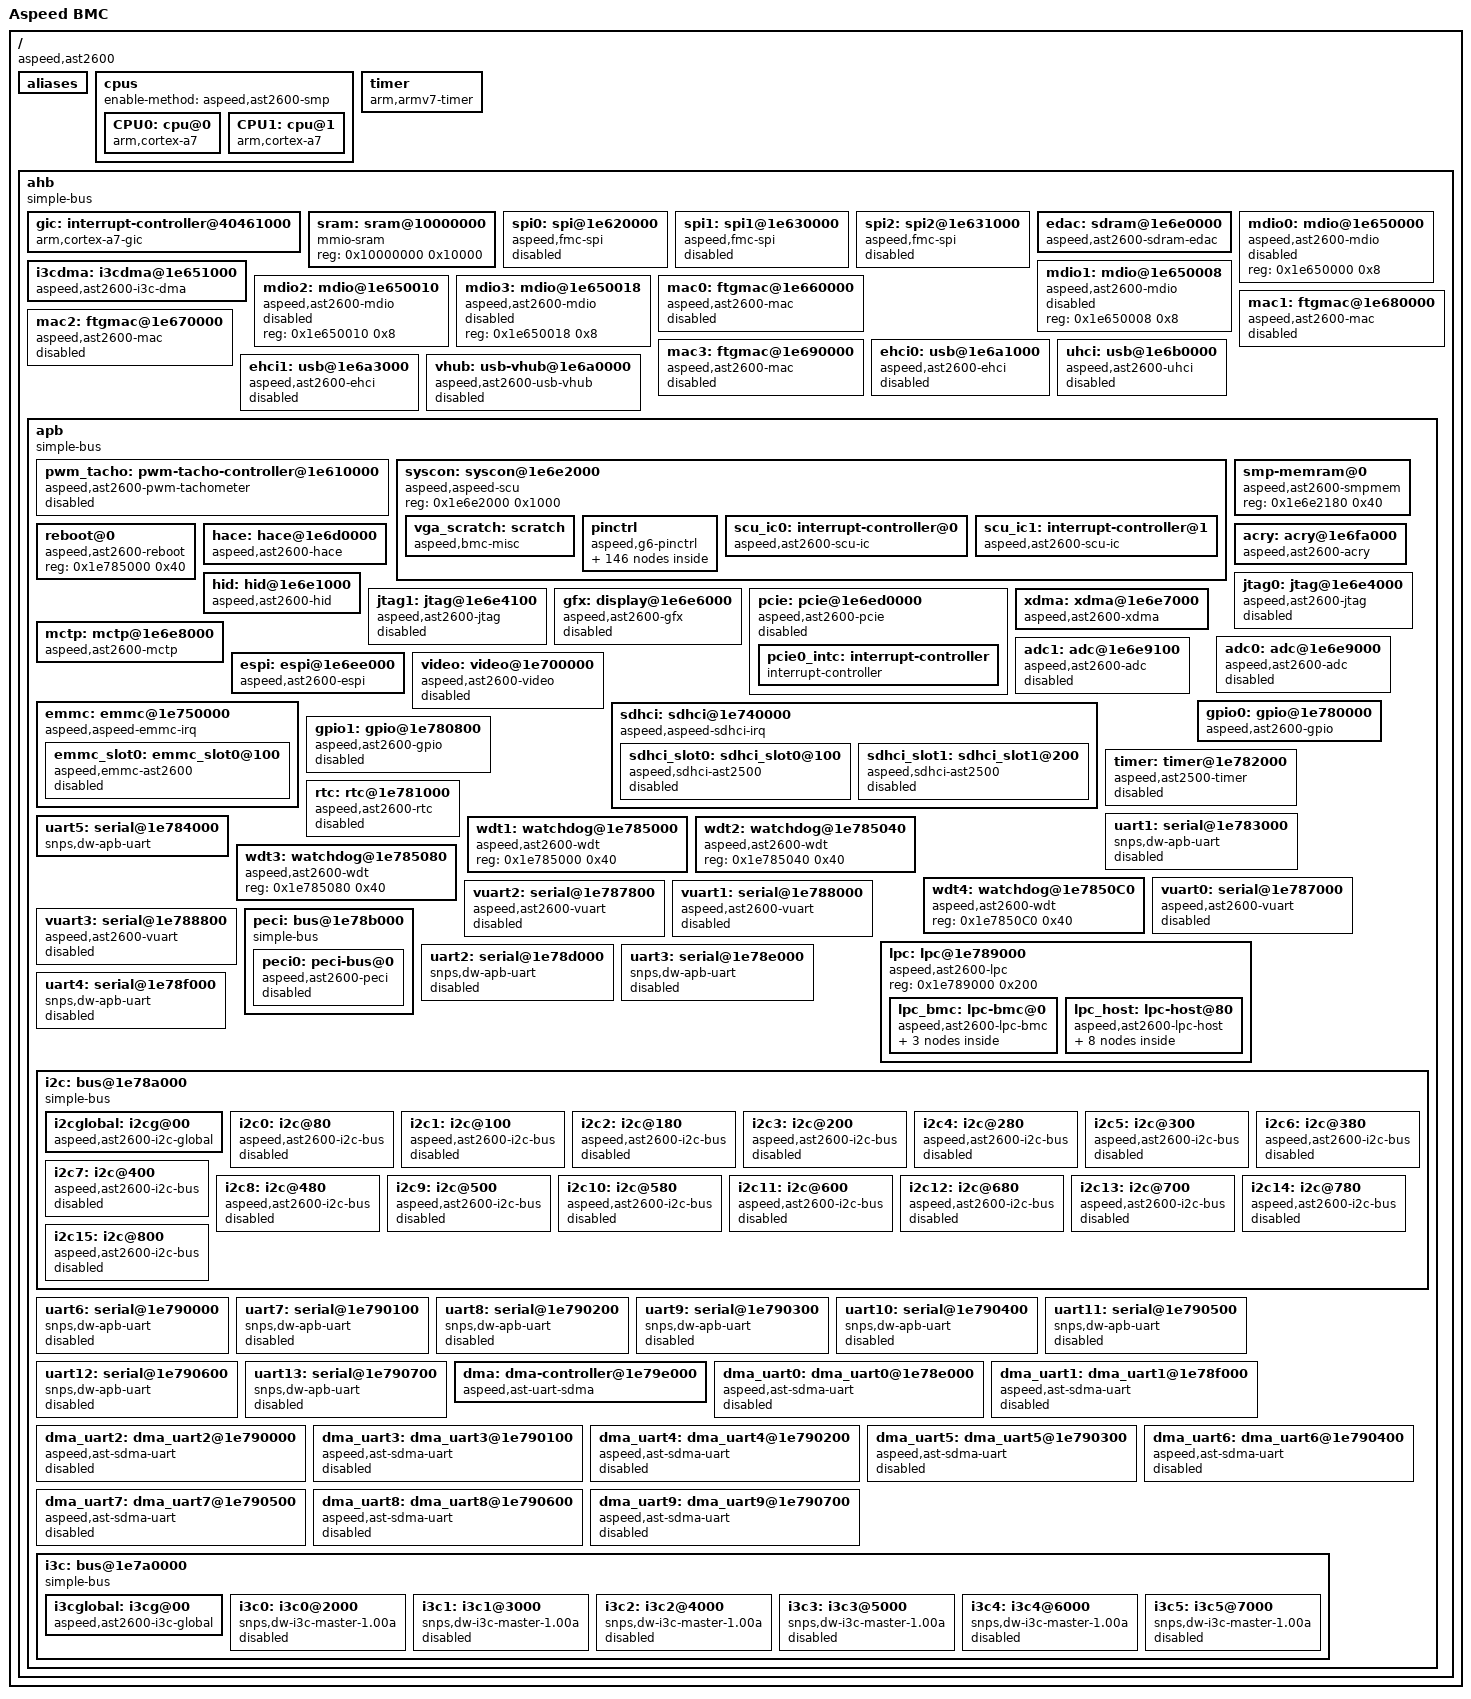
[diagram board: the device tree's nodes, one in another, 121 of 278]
// SPDX-License-Identifier: GPL-2.0+
#include <dt-bindings/interrupt-controller/arm-gic.h>
#include <dt-bindings/clock/aspeed-g6-clock.h>
#include <dt-bindings/gpio/aspeed-gpio.h>
#include <dt-bindings/interrupt-controller/aspeed-scu-irq.h>

/ {
	model = "Aspeed BMC";
	compatible = "aspeed,ast2600";
	#address-cells = <1>;
	#size-cells = <1>;
	interrupt-parent = <&gic>;

	aliases {
		i3c0 = &i3c0;
		i3c1 = &i3c1;
		i3c2 = &i3c2;
		i3c3 = &i3c3;
		i3c4 = &i3c4;
		i3c5 = &i3c5;
		i2c0 = &i2c0;
		i2c1 = &i2c1;
		i2c2 = &i2c2;
		i2c3 = &i2c3;
		i2c4 = &i2c4;
		i2c5 = &i2c5;
		i2c6 = &i2c6;
		i2c7 = &i2c7;
		i2c8 = &i2c8;
		i2c9 = &i2c9;
		i2c10 = &i2c10;
		i2c11 = &i2c11;
		i2c12 = &i2c12;
		i2c13 = &i2c13;
		i2c14 = &i2c14;
		i2c15 = &i2c15;
		serial0 = &uart1;
		serial1 = &uart2;
		serial2 = &uart3;
		serial3 = &uart4;
		serial4 = &uart5;
		serial5 = &uart6;
		serial6 = &uart7;
		serial7 = &uart8;
		serial8 = &uart9;
		serial9 = &uart10;
		serial10 = &uart11;
		serial11 = &uart12;
		serial12 = &uart13;
		serial13 = &vuart0;
		serial14 = &vuart1;
		serial15 = &vuart2;
		serial16 = &vuart3;
		peci0 = &peci0;
	};

	cpus {
		#address-cells = <1>;
		#size-cells = <0>;
		enable-method = "aspeed,ast2600-smp";

		CPU0: cpu@0 {
			compatible = "arm,cortex-a7";
			device_type = "cpu";
			reg = <0xf00>;
			clocks = <&syscon ASPEED_CLK_HPLL>;
		};

		CPU1: cpu@1 {
			compatible = "arm,cortex-a7";
			device_type = "cpu";
			reg = <0xf01>;
			clocks = <&syscon ASPEED_CLK_HPLL>;
		};

	};

	timer {
		compatible = "arm,armv7-timer";
		interrupt-parent = <&gic>;
		interrupts = <GIC_PPI 13 (GIC_CPU_MASK_SIMPLE(2) | IRQ_TYPE_LEVEL_LOW)>,
				<GIC_PPI 14 (GIC_CPU_MASK_SIMPLE(2) | IRQ_TYPE_LEVEL_LOW)>,
				<GIC_PPI 11 (GIC_CPU_MASK_SIMPLE(2) | IRQ_TYPE_LEVEL_LOW)>,
				<GIC_PPI 10 (GIC_CPU_MASK_SIMPLE(2) | IRQ_TYPE_LEVEL_LOW)>;
		clocks = <&syscon ASPEED_CLK_HPLL>;
		arm,cpu-registers-not-fw-configured;
	};

	ahb {
		compatible = "simple-bus";
		#address-cells = <1>;
		#size-cells = <1>;
		device_type = "soc";
		ranges;

		gic: interrupt-controller@40461000 {
				compatible = "arm,cortex-a7-gic";
				interrupts = <GIC_PPI 9 (GIC_CPU_MASK_SIMPLE(2) | IRQ_TYPE_LEVEL_HIGH)>;
				#interrupt-cells = <3>;
				interrupt-controller;
				interrupt-parent = <&gic>;
				reg = <0x40461000 0x1000>,
					<0x40462000 0x1000>,
					<0x40464000 0x2000>,
					<0x40466000 0x2000>;
		};

		sram: sram@10000000 {
			compatible = "mmio-sram";
			reg = <0x10000000 0x10000>;      // 64K
		};

		spi0: spi@1e620000 {
			/* reg : cs0 : cs1 : cs2  */
			reg = <0x1e620000 0x100 
					0x20000000 0x20 
					0x28000000 0x20>;
			#address-cells = <1>;
			#size-cells = <0>;
			compatible = "aspeed,fmc-spi";
			clocks = <&syscon ASPEED_CLK_AHB>;
			status = "disable";
			number_of_chip_select = /bits/ 16 <2>;
			interrupts = <GIC_SPI 39 IRQ_TYPE_LEVEL_HIGH>;
		};

		spi1: spi1@1e630000 {
			/* reg : cs0 : cs1 */
			reg = <0x1e630000 0x100 
					0x30000000 0x20 
					0x32000000 0x20>;
			#address-cells = <1>;
			#size-cells = <0>;
			compatible = "aspeed,fmc-spi";
			clocks = <&syscon ASPEED_CLK_AHB>;
			status = "disable";
			number_of_chip_select = /bits/ 8 <2>;
		};

		spi2: spi2@1e631000 {
			/* reg : cs0 : cs1 */
			reg = <0x1e631000 0x100 
					0x38000000 0x20 
					0x3A000000 0x20>;
			#address-cells = <1>;
			#size-cells = <0>;
			compatible = "aspeed,fmc-spi";
			clocks = <&syscon ASPEED_CLK_AHB>;
			status = "disable";
			number_of_chip_select = /bits/ 8 <2>;
		};

		edac: sdram@1e6e0000 {
			compatible = "aspeed,ast2600-sdram-edac";
			reg = <0x1e6e0000 0x174>;
			interrupts = <GIC_SPI 0 IRQ_TYPE_LEVEL_HIGH>;
		};

		i3cdma: i3cdma@1e651000 {
			compatible = "aspeed,ast2600-i3c-dma";
			reg = <0x1e651000 0x1000>;
			resets = <&syscon ASPEED_RESET_I3C>;
		};

		mdio0: mdio@1e650000 {
			compatible = "aspeed,ast2600-mdio";
			reg = <0x1e650000 0x8>;
			#address-cells = <1>;
			#size-cells = <0>;
			status = "disabled";
		};

		mdio1: mdio@1e650008 {
			compatible = "aspeed,ast2600-mdio";
			reg = <0x1e650008 0x8>;
			#address-cells = <1>;
			#size-cells = <0>;
			status = "disabled";
		};

		mdio2: mdio@1e650010 {
			compatible = "aspeed,ast2600-mdio";
			reg = <0x1e650010 0x8>;
			#address-cells = <1>;
			#size-cells = <0>;
			status = "disabled";
		};

		mdio3: mdio@1e650018 {
			compatible = "aspeed,ast2600-mdio";
			reg = <0x1e650018 0x8>;
			#address-cells = <1>;
			#size-cells = <0>;
			status = "disabled";
		};

		mac0: ftgmac@1e660000 {
			compatible = "aspeed,ast2600-mac", "faraday,ftgmac100";
			reg = <0x1e660000 0x180>;
			#address-cells = <1>;
			#size-cells = <0>;
			interrupts = <GIC_SPI 2 IRQ_TYPE_LEVEL_HIGH>;
			clocks = <&syscon ASPEED_CLK_GATE_MAC1CLK>;

			status = "disabled";
		};

		mac1: ftgmac@1e680000 {
			compatible = "aspeed,ast2600-mac", "faraday,ftgmac100";
			reg = <0x1e680000 0x180>;
			#address-cells = <1>;
			#size-cells = <0>;
			interrupts = <GIC_SPI 3 IRQ_TYPE_LEVEL_HIGH>;
			clocks = <&syscon ASPEED_CLK_GATE_MAC2CLK>;

			status = "disabled";
		};

		mac2: ftgmac@1e670000 {
			compatible = "aspeed,ast2600-mac", "faraday,ftgmac100";
			reg = <0x1e670000 0x180>;
			#address-cells = <1>;
			#size-cells = <0>;
			interrupts = <GIC_SPI 32 IRQ_TYPE_LEVEL_HIGH>;
			clocks = <&syscon ASPEED_CLK_GATE_MAC3CLK>;

			status = "disabled";
		};

		mac3: ftgmac@1e690000 {
			compatible = "aspeed,ast2600-mac", "faraday,ftgmac100";
			reg = <0x1e690000 0x180>;
			#address-cells = <1>;
			#size-cells = <0>;
			interrupts = <GIC_SPI 33 IRQ_TYPE_LEVEL_HIGH>;
			clocks = <&syscon ASPEED_CLK_GATE_MAC4CLK>;

			status = "disabled";
		};

		ehci0: usb@1e6a1000 {
			compatible = "aspeed,ast2600-ehci", "generic-ehci";
			reg = <0x1e6a1000 0x100>;
			interrupts = <GIC_SPI 5 IRQ_TYPE_LEVEL_HIGH>;
			clocks = <&syscon ASPEED_CLK_GATE_USBPORT1CLK>;
			pinctrl-names = "default";
			pinctrl-0 = <&pinctrl_usb2ah_default>;
			status = "disabled";
		};

		ehci1: usb@1e6a3000 {
			compatible = "aspeed,ast2600-ehci", "generic-ehci";
			reg = <0x1e6a3000 0x100>;
			interrupts = <GIC_SPI 9 IRQ_TYPE_LEVEL_HIGH>;
			clocks = <&syscon ASPEED_CLK_GATE_USBPORT2CLK>;
			pinctrl-names = "default";
			pinctrl-0 = <&pinctrl_usb2bh_default>;
			status = "disabled";
		};

		uhci: usb@1e6b0000 {
			compatible = "aspeed,ast2600-uhci", "generic-uhci";
			reg = <0x1e6b0000 0x100>;
			interrupts = <GIC_SPI 10 IRQ_TYPE_LEVEL_HIGH>;
			#ports = <2>;
			clocks = <&syscon ASPEED_CLK_GATE_USBUHCICLK>;
			status = "disabled";
		};

		vhub: usb-vhub@1e6a0000 {
			compatible = "aspeed,ast2600-usb-vhub";
			reg = <0x1e6a0000 0x300>;
			interrupts = <GIC_SPI 5 IRQ_TYPE_LEVEL_HIGH>;
			clocks = <&syscon ASPEED_CLK_GATE_USBPORT1CLK>;
			status = "disabled";
		};

		apb {
			compatible = "simple-bus";
			#address-cells = <1>;
			#size-cells = <1>;
			ranges;

			pwm_tacho: pwm-tacho-controller@1e610000 {
				compatible = "aspeed,ast2600-pwm-tachometer";
				#address-cells = <1>;
				#size-cells = <0>;
				reg = <0x1e610000 0x100>;
				clocks = <&syscon ASPEED_CLK_AHB>;
				resets = <&syscon ASPEED_RESET_PWM>;
				status = "disabled";

			};

			syscon: syscon@1e6e2000 {
				compatible = "aspeed,aspeed-scu", "aspeed,ast2600-scu", "syscon", "simple-mfd";
				reg = <0x1e6e2000 0x1000>;
				ranges = <0 0x1e6e2000 0x1000>;
				#address-cells = <1>;
				#size-cells = <1>;
				#clock-cells = <1>;
				#reset-cells = <1>;

				vga_scratch: scratch {
					compatible = "aspeed,bmc-misc";
				};

				pinctrl: pinctrl {
					compatible = "aspeed,g6-pinctrl";
				};

				scu_ic0: interrupt-controller@0 {
					#interrupt-cells = <1>;
					compatible = "aspeed,ast2600-scu-ic";
					reg = <0x560 0x10>;
					interrupt-parent = <&gic>;
					interrupts = <GIC_SPI 12 IRQ_TYPE_LEVEL_HIGH>;
					interrupt-controller;
					parity-check;
				};

				scu_ic1: interrupt-controller@1 {
					#interrupt-cells = <1>;
					compatible = "aspeed,ast2600-scu-ic";
					reg = <0x570 0x10>;
					interrupt-parent = <&gic>;
					interrupts = <GIC_SPI 41 IRQ_TYPE_LEVEL_HIGH>;
					interrupt-controller;
				};

			};

			smp-memram@0 {
				compatible = "aspeed,ast2600-smpmem", "syscon";
				reg = <0x1e6e2180 0x40>;
			};

			reboot@0 {
				compatible = "aspeed,ast2600-reboot", "syscon";
				reg = <0x1e785000 0x40>;
			};

			hace: hace@1e6d0000 {
				compatible = "aspeed,ast2600-hace";
				reg = <0x1e6d0000 0x200>;
				interrupts = <GIC_SPI 4 IRQ_TYPE_LEVEL_HIGH>;
				clocks = <&syscon ASPEED_CLK_GATE_YCLK>;
				clock-names = "yclk";
				resets = <&syscon ASPEED_RESET_HACE>;
			};

			acry: acry@1e6fa000 {
				compatible = "aspeed,ast2600-acry";
				reg = <0x1e6fa000 0x400 0x1e710000 0x1800>;
				interrupts = <GIC_SPI 160 IRQ_TYPE_LEVEL_HIGH>;
				clocks = <&syscon ASPEED_CLK_GATE_RSACLK>;
				clock-names = "rsaclk";
			};

			hid: hid@1e6e1000 {
				compatible = "aspeed,ast2600-hid";
				reg= <0x1e6e1000 0x20>;
				interrupts = <GIC_SPI 9 IRQ_TYPE_LEVEL_HIGH>;
				clocks = <&syscon ASPEED_CLK_GATE_USBPORT2CLK>;
				resets = <&syscon ASPEED_RESET_EHCI_P2>;
				reset-names = "hid";
				pinctrl-names = "default";
				pinctrl-0 = <&pinctrl_usb11bhid_default>;
			};

			jtag0: jtag@1e6e4000 {
				compatible = "aspeed,ast2600-jtag";
				reg= <0x1e6e4000 0x20>;
				interrupts = <GIC_SPI 27 IRQ_TYPE_LEVEL_HIGH>;
				clocks = <&syscon ASPEED_CLK_AHB>;
				resets = <&syscon ASPEED_RESET_JTAG_MASTER>;
				reset-names = "jtag";
				status = "disabled";
			};

			jtag1: jtag@1e6e4100 {
				compatible = "aspeed,ast2600-jtag";
				reg= <0x1e6e4100 0x20>;
				interrupts = <GIC_SPI 53 IRQ_TYPE_LEVEL_HIGH>;
				clocks = <&syscon ASPEED_CLK_AHB>;
				resets = <&syscon ASPEED_RESET_JTAG_MASTER2>;
				reset-names = "jtag";
				pinctrl-names = "default";
				pinctrl-0 = <&pinctrl_jtagm_default>;
				status = "disabled";
			};

			gfx: display@1e6e6000 {
				compatible = "aspeed,ast2600-gfx", "syscon";
				reg = <0x1e6e6000 0x1000>;
				reg-io-width = <4>;
				clocks = <&syscon ASPEED_CLK_GATE_D1CLK>;
				resets = <&syscon ASPEED_RESET_CRT>, <&syscon ASPEED_RESET_GRAPHICS>;
				reset-names = "crt", "engine";
				interrupts = <GIC_SPI 14 IRQ_TYPE_LEVEL_HIGH>;
				status = "disabled";
			};

			pcie: pcie@1e6ed0000 {
				compatible = "aspeed,ast2600-pcie";
				reg = <0x1e6ed200 0x100 0x1e770000 0x100>;
				reg-names = "pciebreg", "h2xreg";
				device_type = "pci";
				bus-range = <0x00 0xff>;

				#address-cells = <3>;
				#size-cells = <2>;
				#interrupt-cells = <1>;
#if 1
				ranges = < 0x02000000 0 0x60000000 0x60000000 0 0x10000000 >;
#else
				ranges = <0x01000000 0 0x60000000 0x60000000 0 0x10000000   /* I/O */
                                          0x02000000 0 0x70000000 0x70000000 0 0x10000000>; /* memory */
#endif
				interrupts = <GIC_SPI 29 IRQ_TYPE_LEVEL_HIGH>;

				status = "disabled";

				linux,pci-domain = <0>;
				pcie0_intc: interrupt-controller {
					interrupt-controller;
					#address-cells = <0>;
					#interrupt-cells = <1>;
				};

			};

			xdma: xdma@1e6e7000 {
				compatible = "aspeed,ast2600-xdma";
				reg = <0x1e6e7000 0x80>;
				interrupts-extended = <&gic GIC_SPI 6 IRQ_TYPE_LEVEL_HIGH>, <&scu_ic0 ASPEED_SCU_PCIE_REST_LOW_TO_HIGH>;
				resets = <&syscon ASPEED_RESET_DEV_XDMA>;
			};

			mctp: mctp@1e6e8000 {
				compatible = "aspeed,ast2600-mctp";
				reg = <0x1e6e8000 0x30>;
	 			interrupts-extended = <&gic GIC_SPI 26 IRQ_TYPE_LEVEL_HIGH>, <&scu_ic0 ASPEED_SCU_PCIE_REST_LOW_TO_HIGH>;
				resets = <&syscon ASPEED_RESET_DEV_MCTP>;
			};

			adc0: adc@1e6e9000 {
				compatible = "aspeed,ast2600-adc";
				reg = <0x1e6e9000 0x100>;
				clocks = <&syscon ASPEED_CLK_APB2>;
				resets = <&syscon ASPEED_RESET_ADC>;
				interrupts = <GIC_SPI 46 IRQ_TYPE_LEVEL_HIGH>;
				#io-channel-cells = <1>;
				status = "disabled"; 
			}; 

			adc1: adc@1e6e9100 {
				compatible = "aspeed,ast2600-adc";
				reg = <0x1e6e9100 0x100>;
				clocks = <&syscon ASPEED_CLK_APB2>;
				resets = <&syscon ASPEED_RESET_ADC>;
				interrupts = <GIC_SPI 46 IRQ_TYPE_LEVEL_HIGH>;
				#io-channel-cells = <1>;
				status = "disabled";
			};

			espi: espi@1e6ee000 {
				compatible = "aspeed,ast2600-espi";
				reg = <0x1e6ee000 0x200>;
				interrupts-extended = <&gic GIC_SPI 42 IRQ_TYPE_LEVEL_HIGH>, <&gpio0 ASPEED_GPIO(W, 7) IRQ_TYPE_EDGE_FALLING>;
				resets = <&syscon ASPEED_RESET_LPC_ESPI>;
			};

#if 0
			video: video@1e700000 {
				compatible = "aspeed,ast2600-video-engine";
				reg = <0x1e700000 0x1000>;
				clocks = <&syscon ASPEED_CLK_GATE_VCLK>,
					 <&syscon ASPEED_CLK_GATE_ECLK>;
				clock-names = "vclk", "eclk";
				interrupts = <GIC_SPI 7 IRQ_TYPE_LEVEL_HIGH>;
				status = "disabled";
			};
#else
			video: video@1e700000 {
				compatible = "aspeed,ast2600-video";
				/* 184MB : 40MB*/
				reg = <0x1e700000 0x300>;
				clocks = <&syscon ASPEED_CLK_GATE_VCLK>, 
				<&syscon ASPEED_CLK_GATE_ECLK>;
				clock-names = "vclk", "eclk";
				interrupts = <GIC_SPI 7 IRQ_TYPE_LEVEL_HIGH>;
				resets = <&syscon ASPEED_RESET_VIDEO>;
				status = "disabled";
			};
#endif

			sdhci: sdhci@1e740000 {
				#interrupt-cells = <1>;
				compatible = "aspeed,aspeed-sdhci-irq", "simple-mfd";
				reg = <0x1e740000 0x1000>;
				interrupts = <GIC_SPI 43 IRQ_TYPE_LEVEL_HIGH>;
				interrupt-controller;
				clocks = <&syscon ASPEED_CLK_GATE_SDCLK>, <&syscon ASPEED_CLK_GATE_SDEXTCLK>;
				clock-names = "ctrlclk", "extclk";
				#address-cells = <1>;
				#size-cells = <1>;
				ranges = <0x0 0x1e740000 0x1000>;
				slot0-wp-inverse;
				slot1-wp-inverse;

				sdhci_slot0: sdhci_slot0@100 {
					compatible = "aspeed,sdhci-ast2500";
					reg = <0x100 0x100>;
					interrupts = <0>;
					interrupt-parent = <&sdhci>;
					sdhci,auto-cmd12;
					clocks = <&syscon ASPEED_CLK_SDIO>;
					power-gpio = <&gpio0 ASPEED_GPIO(V, 0) GPIO_ACTIVE_LOW>;
					power-switch-gpio = <&gpio0 ASPEED_GPIO(V, 1) GPIO_ACTIVE_LOW>;
					pinctrl-names = "default";
					pinctrl-0 = <&pinctrl_sd1_default>;
					status = "disabled";
				};

				sdhci_slot1: sdhci_slot1@200 {
					compatible = "aspeed,sdhci-ast2500";
					reg = <0x200 0x100>;
					interrupts = <1>;
					interrupt-parent = <&sdhci>;
					sdhci,auto-cmd12;
					clocks = <&syscon ASPEED_CLK_SDIO>;
					power-gpio = <&gpio0 ASPEED_GPIO(V, 2) GPIO_ACTIVE_LOW>;
                                        power-switch-gpio = <&gpio0 ASPEED_GPIO(V, 3) GPIO_ACTIVE_LOW>;
					pinctrl-names = "default";
					pinctrl-0 = <&pinctrl_sd2_default>;
					status = "disabled";
				};

			};

			emmc: emmc@1e750000 {
				#interrupt-cells = <1>;
				compatible = "aspeed,aspeed-emmc-irq", "simple-mfd";
				reg = <0x1e750000 0x1000>;
				interrupts = <GIC_SPI 15 IRQ_TYPE_LEVEL_HIGH>;
				interrupt-controller;
				clocks = <&syscon ASPEED_CLK_GATE_EMMCCLK>, <&syscon ASPEED_CLK_GATE_EMMCEXTCLK>;
				clock-names = "ctrlclk", "extclk";
				#address-cells = <1>;
				#size-cells = <1>;
				ranges = <0x0 0x1e750000 0x1000>;

				emmc_slot0: emmc_slot0@100 {
					compatible = "aspeed,emmc-ast2600";
					reg = <0x100 0x100>;
					interrupts = <0>;
					interrupt-parent = <&emmc>;
					sdhci,auto-cmd12;
					clocks = <&syscon ASPEED_CLK_GATE_EMMCEXTCLK>;
					pinctrl-names = "default";
					pinctrl-0 = <&pinctrl_emmc_default>;
					status = "disabled";
				};

			};

			gpio0: gpio@1e780000 {
				#gpio-cells = <2>;
				gpio-controller;
				compatible = "aspeed,ast2600-gpio";
				reg = <0x1e780000 0x800>;
				interrupts = <GIC_SPI 40 IRQ_TYPE_LEVEL_HIGH>;
				gpio-ranges = <&pinctrl 0 0 248>;
				clocks = <&syscon ASPEED_CLK_APB2>;
				interrupt-controller;
				#interrupt-cells = <2>;
			};

			gpio1: gpio@1e780800 {
				#gpio-cells = <2>;
				gpio-controller;
				compatible = "aspeed,ast2600-gpio";
				reg = <0x1e780800 0x800>;
				interrupts = <GIC_SPI 11 IRQ_TYPE_LEVEL_HIGH>;
				gpio-ranges = <&pinctrl 0 0 248>;
				clocks = <&syscon ASPEED_CLK_APB1>;
				interrupt-controller;
				#interrupt-cells = <2>;
				status = "disabled";
			};

			timer: timer@1e782000 {
				/* This timer is a Faraday FTTMR010 derivative */
				compatible = "aspeed,ast2500-timer";
				reg = <0x1e782000 0x90>;
				interrupts-extended = <&gic  GIC_SPI 16 IRQ_TYPE_LEVEL_HIGH>,
						  <&gic  GIC_SPI 17 IRQ_TYPE_LEVEL_HIGH>,
						  <&gic  GIC_SPI 18 IRQ_TYPE_LEVEL_HIGH>,
						  <&gic  GIC_SPI 19 IRQ_TYPE_LEVEL_HIGH>,
						  <&gic  GIC_SPI 20 IRQ_TYPE_LEVEL_HIGH>,
						  <&gic  GIC_SPI 21 IRQ_TYPE_LEVEL_HIGH>,
						  <&gic  GIC_SPI 22 IRQ_TYPE_LEVEL_HIGH>,
						  <&gic  GIC_SPI 23 IRQ_TYPE_LEVEL_HIGH>;
				clocks = <&syscon ASPEED_CLK_APB1>;
				clock-names = "PCLK";
				status = "disabled";
			};

			rtc: rtc@1e781000 {
				compatible = "aspeed,ast2600-rtc";
				reg = <0x1e781000 0x18>;
				interrupts = <GIC_SPI 13 IRQ_TYPE_LEVEL_HIGH>;
				status = "disabled";
			};

			uart1: serial@1e783000 {
				compatible = "snps,dw-apb-uart";
				reg = <0x1e783000 0x20>;
				reg-shift = <2>;
				reg-io-width = <4>;
				interrupts = <GIC_SPI 47 IRQ_TYPE_LEVEL_HIGH>;
				clocks = <&syscon ASPEED_CLK_GATE_UART1CLK>;
				resets = <&lpc_reset 4>;
				no-loopback-test;
				pinctrl-names = "default";
				pinctrl-0 = <&pinctrl_txd1_default &pinctrl_rxd1_default>;

				status = "disabled";	
			};

			uart5: serial@1e784000 {
				compatible = "snps,dw-apb-uart";
				reg = <0x1e784000 0x1000>;
				reg-shift = <2>;
				reg-io-width = <4>;
				interrupts = <GIC_SPI 8 IRQ_TYPE_LEVEL_HIGH>;
				clocks = <&syscon ASPEED_CLK_GATE_UART5CLK>;
				no-loopback-test;
			};

			wdt1: watchdog@1e785000 {
				compatible = "aspeed,ast2600-wdt";
				reg = <0x1e785000 0x40>;
			};

			wdt2: watchdog@1e785040 {
				compatible = "aspeed,ast2600-wdt";
				reg = <0x1e785040 0x40>;
			};

			wdt3: watchdog@1e785080 {
				compatible = "aspeed,ast2600-wdt";
				reg = <0x1e785080 0x40>;
			};

			wdt4: watchdog@1e7850C0 {
				compatible = "aspeed,ast2600-wdt";
				reg = <0x1e7850C0 0x40>;
			};

			vuart0: serial@1e787000 {
				compatible = "aspeed,ast2600-vuart";
				reg = <0x1e787000 0x40>;
				reg-shift = <2>;
				interrupts = <GIC_SPI 147 IRQ_TYPE_LEVEL_HIGH>;
				clocks = <&syscon ASPEED_CLK_APB1>;
				no-loopback-test;
				port_address = <0x3f8>;
				serial_irq = <4>;

				status = "disabled";
			};

			vuart2: serial@1e787800 {
				compatible = "aspeed,ast2600-vuart";
				reg = <0x1e787800 0x40>;
				reg-shift = <2>;
				interrupts = <GIC_SPI 147 IRQ_TYPE_LEVEL_HIGH>;
				clocks = <&syscon ASPEED_CLK_APB1>;
				no-loopback-test;
				port_address = <0x3f8>;
				serial_irq = <4>;

				status = "disabled";
            };

			vuart1: serial@1e788000 {
				compatible = "aspeed,ast2600-vuart";
				reg = <0x1e788000 0x40>;
				reg-shift = <2>;
				interrupts = <GIC_SPI 148 IRQ_TYPE_LEVEL_HIGH>;
				clocks = <&syscon ASPEED_CLK_APB2>;
				no-loopback-test;
				port_address = <0x2f8>;
				serial_irq = <3>;

				status = "disabled";
			};

			vuart3: serial@1e788800 {
                                compatible = "aspeed,ast2600-vuart";
                                reg = <0x1e788800 0x40>;
                                reg-shift = <2>;
                                interrupts = <GIC_SPI 148 IRQ_TYPE_LEVEL_HIGH>;
                                clocks = <&syscon ASPEED_CLK_APB2>;
                                no-loopback-test;
                                port_address = <0x2f8>;
                                serial_irq = <3>;

                                status = "disabled";
                        };

			lpc: lpc@1e789000 {
				compatible = "aspeed,ast2600-lpc", "simple-mfd";
				reg = <0x1e789000 0x200>;

				#address-cells = <1>;
				#size-cells = <1>;
				ranges = <0x0 0x1e789000 0x1000>;

				lpc_bmc: lpc-bmc@0 {
					compatible = "aspeed,ast2600-lpc-bmc", "simple-mfd", "syscon";
					reg = <0x0 0x80>;
					reg-io-width = <4>;

					#address-cells = <1>;
					#size-cells = <1>;
					ranges = <0x0 0x0 0x80>;

					kcs1: kcs1@0 {
						compatible = "aspeed,ast2600-kcs-bmc";
						interrupts = <GIC_SPI 138 IRQ_TYPE_LEVEL_HIGH>;
						kcs_chan = <1>;
						kcs_addr = <0xCA0>;
						status = "disabled";
					};

					kcs2: kcs2@0 {
						compatible = "aspeed,ast2600-kcs-bmc";
						interrupts = <GIC_SPI 139 IRQ_TYPE_LEVEL_HIGH>;
						kcs_chan = <2>;
						kcs_addr = <0xCA8>;
						status = "disabled";
					};

					kcs3: kcs3@0 {
						compatible = "aspeed,ast2600-kcs-bmc";
						interrupts = <GIC_SPI 140 IRQ_TYPE_LEVEL_HIGH>;
						kcs_chan = <3>;
						kcs_addr = <0xCA2>;
					};
				};

				lpc_host: lpc-host@80 {
					compatible = "aspeed,ast2600-lpc-host", "simple-mfd", "syscon";
					reg = <0x80 0x1e0>;
					reg-io-width = <4>;

					#address-cells = <1>;
					#size-cells = <1>;
					ranges = <0x0 0x80 0x1e0>;

					kcs4: kcs4@0 {
						compatible = "aspeed,ast2500-kcs-bmc";
						interrupts = <GIC_SPI 141 IRQ_TYPE_LEVEL_HIGH>;
						kcs_chan = <4>;
						status = "disabled";
					};

					lpc_ctrl: lpc-ctrl@0 {
						compatible = "aspeed,ast2600-lpc-ctrl";
						reg = <0x0 0x80>;
						clocks = <&syscon ASPEED_CLK_GATE_LCLK>;
						status = "disabled";
					};

					lpc_snoop: lpc-snoop@0 {
						compatible = "aspeed,ast2600-lpc-snoop";
						reg = <0x0 0x80>;
						interrupts = <GIC_SPI 144 IRQ_TYPE_LEVEL_HIGH>;
						snoop-ports = <0x80>;
					};

					lhc: lhc@20 {
						compatible = "aspeed,ast2600-lhc";
						reg = <0x20 0x24 0x48 0x8>;
					};

					lpc_reset: reset-controller@18 {
						compatible = "aspeed,ast2600-lpc-reset";
						reg = <0x18 0x4>;
						#reset-cells = <1>;
					};

					ibt: ibt@c0 {
						compatible = "aspeed,ast2600-ibt-bmc";
						reg = <0xc0 0x18>;
						interrupts = <GIC_SPI 143 IRQ_TYPE_LEVEL_HIGH>;
					};

					sio_regs: regs {
						compatible = "aspeed,bmc-misc";
					};

					mbox: mbox@180 {
						compatible = "aspeed,ast2600-mbox";
						reg = <0x180 0x5c>;
						interrupts = <GIC_SPI 54 IRQ_TYPE_LEVEL_HIGH>;
						#mbox-cells = <1>;
					};
				};
			};

			peci: bus@1e78b000 {
				compatible = "simple-bus";
				#address-cells = <1>;
				#size-cells = <1>;
				ranges = <0x0 0x1e78b000 0x100>;
			};

			uart2: serial@1e78d000 {
				compatible = "snps,dw-apb-uart";
				reg = <0x1e78d000 0x20>;
				reg-shift = <2>;
				reg-io-width = <4>;
				interrupts = <GIC_SPI 48 IRQ_TYPE_LEVEL_HIGH>;
				clocks = <&syscon ASPEED_CLK_GATE_UART2CLK>;
				resets = <&lpc_reset 5>;
				no-loopback-test;
				pinctrl-names = "default";
				pinctrl-0 = <&pinctrl_txd2_default &pinctrl_rxd2_default>;

				status = "disabled";
			};

			uart3: serial@1e78e000 {
				compatible = "snps,dw-apb-uart";
				reg = <0x1e78e000 0x20>;
				reg-shift = <2>;
				reg-io-width = <4>;
				interrupts = <GIC_SPI 49 IRQ_TYPE_LEVEL_HIGH>;
				clocks = <&syscon ASPEED_CLK_GATE_UART3CLK>;
				resets = <&lpc_reset 6>;
				no-loopback-test;
				pinctrl-names = "default";
				pinctrl-0 = <&pinctrl_txd3_default &pinctrl_rxd3_default>;

				status = "disabled";
			};

			uart4: serial@1e78f000 {
				compatible = "snps,dw-apb-uart";
				reg = <0x1e78f000 0x20>;
				reg-shift = <2>;
				reg-io-width = <4>;
				interrupts = <GIC_SPI 50 IRQ_TYPE_LEVEL_HIGH>;
				clocks = <&syscon ASPEED_CLK_GATE_UART4CLK>;
				resets = <&lpc_reset 7>;
				no-loopback-test;
				pinctrl-names = "default";
				pinctrl-0 = <&pinctrl_txd4_default &pinctrl_rxd4_default>;

				status = "disabled";
			};

			i2c: bus@1e78a000 {
				compatible = "simple-bus";
				#address-cells = <1>;
				#size-cells = <1>;
				ranges = <0 0x1e78a000 0x1000>;
			};

			uart6: serial@1e790000 {
				compatible = "snps,dw-apb-uart";
				reg = <0x1e790000 0x20>;
				reg-shift = <2>;
				reg-io-width = <4>;
				interrupts = <GIC_SPI 57 IRQ_TYPE_LEVEL_HIGH>;
				clocks = <&syscon ASPEED_CLK_GATE_UART6CLK>;
				no-loopback-test;
				pinctrl-names = "default";
				pinctrl-0 = <&pinctrl_uart6_default>;

				status = "disabled";
			};

			uart7: serial@1e790100 {
				compatible = "snps,dw-apb-uart";
				reg = <0x1e790100 0x20>;
				reg-shift = <2>;
				reg-io-width = <4>;
				interrupts = <GIC_SPI 58 IRQ_TYPE_LEVEL_HIGH>;
				clocks = <&syscon ASPEED_CLK_GATE_UART7CLK>;
				no-loopback-test;
				pinctrl-names = "default";
				pinctrl-0 = <&pinctrl_uart7_default>;

				status = "disabled";
			};

			uart8: serial@1e790200 {
				compatible = "snps,dw-apb-uart";
				reg = <0x1e790200 0x20>;
				reg-shift = <2>;
				reg-io-width = <4>;
				interrupts = <GIC_SPI 59 IRQ_TYPE_LEVEL_HIGH>;
				clocks = <&syscon ASPEED_CLK_GATE_UART8CLK>;
				no-loopback-test;
				pinctrl-names = "default";
				pinctrl-0 = <&pinctrl_uart8_default>;

				status = "disabled";
			};

			uart9: serial@1e790300 {
				compatible = "snps,dw-apb-uart";
				reg = <0x1e790300 0x20>;
				reg-shift = <2>;
				reg-io-width = <4>;
				interrupts = <GIC_SPI 60 IRQ_TYPE_LEVEL_HIGH>;
				clocks = <&syscon ASPEED_CLK_GATE_UART9CLK>;
				no-loopback-test;
				pinctrl-names = "default";
                                pinctrl-0 = <&pinctrl_uart9_default>;

				status = "disabled";
			};

			uart10: serial@1e790400 {
				compatible = "snps,dw-apb-uart";
				reg = <0x1e790400 0x20>;
				reg-shift = <2>;
				reg-io-width = <4>;
				interrupts = <GIC_SPI 61 IRQ_TYPE_LEVEL_HIGH>;
				clocks = <&syscon ASPEED_CLK_GATE_UART10CLK>;
				no-loopback-test;
				pinctrl-names = "default";
				pinctrl-0 = <&pinctrl_uart10_default>;

				status = "disabled";
			};

			uart11: serial@1e790500 {
				compatible = "snps,dw-apb-uart";
				reg = <0x1e790500 0x20>;
				reg-shift = <2>;
				reg-io-width = <4>;
				interrupts = <GIC_SPI 62 IRQ_TYPE_LEVEL_HIGH>;
				clocks = <&syscon ASPEED_CLK_GATE_UART11CLK>;
				no-loopback-test;
				pinctrl-names = "default";
				pinctrl-0 = <&pinctrl_uart11_default>;

				status = "disabled";
			};

			uart12: serial@1e790600 {
				compatible = "snps,dw-apb-uart";
				reg = <0x1e790600 0x20>;
				reg-shift = <2>;
				reg-io-width = <4>;
				interrupts = <GIC_SPI 63 IRQ_TYPE_LEVEL_HIGH>;
				clocks = <&syscon ASPEED_CLK_GATE_UART12CLK>;
				no-loopback-test;
				pinctrl-names = "default";
				pinctrl-0 = <&pinctrl_uart12g1_default>;

				status = "disabled";
			};

			uart13: serial@1e790700 {
				compatible = "snps,dw-apb-uart";
				reg = <0x1e790700 0x20>;
				reg-shift = <2>;
				reg-io-width = <4>;
				interrupts = <GIC_SPI 64 IRQ_TYPE_LEVEL_HIGH>;
				clocks = <&syscon ASPEED_CLK_GATE_UART13CLK>;
				no-loopback-test;
				pinctrl-names = "default";
				pinctrl-0 = <&pinctrl_uart13g1_default>;

				status = "disabled";
			};

			dma: dma-controller@1e79e000 {
				compatible = "aspeed,ast-uart-sdma";
				reg = <0x1e79e000 0x400>;
				interrupts = <GIC_SPI 56 IRQ_TYPE_LEVEL_HIGH>;
				#dma-cells = <1>;
			};

			dma_uart0: dma_uart0@1e78e000 {
				compatible = "aspeed,ast-sdma-uart";
				reg = <0x1e78e000 0x20>;
				interrupts = <GIC_SPI 49 IRQ_TYPE_LEVEL_HIGH>;
				clock-frequency = <1846154>;
				reg-shift = <2>;
				dma-channel = <2>;
				no-loopback-test;
				status = "disabled";
			};

			dma_uart1: dma_uart1@1e78f000 {
				compatible = "aspeed,ast-sdma-uart";
				reg = <0x1e78f000 0x20>;
				interrupts = <GIC_SPI 50 IRQ_TYPE_LEVEL_HIGH>;
				clock-frequency = <1846154>;
				reg-shift = <2>;
				dma-channel = <3>;
				no-loopback-test;
				status = "disabled";
			};

			dma_uart2: dma_uart2@1e790000{
				compatible = "aspeed,ast-sdma-uart";
				reg = <0x1e790000 0x20>;
				interrupts = <GIC_SPI 57 IRQ_TYPE_LEVEL_HIGH>;
				clock-frequency = <1846154>;
				reg-shift = <2>;
				dma-channel = <4>;
				no-loopback-test;
				status = "disabled";
			};

			dma_uart3: dma_uart3@1e790100{
				compatible = "aspeed,ast-sdma-uart";
				reg = <0x1e790100 0x20>;
				interrupts = <GIC_SPI 58 IRQ_TYPE_LEVEL_HIGH>;
				clock-frequency = <1846154>;
				reg-shift = <2>;
				dma-channel = <5>;
				no-loopback-test;
				status = "disabled";
			};

			dma_uart4: dma_uart4@1e790200{
				compatible = "aspeed,ast-sdma-uart";
				reg = <0x1e790200 0x20>;
				interrupts = <GIC_SPI 59 IRQ_TYPE_LEVEL_HIGH>;
				clock-frequency = <1846154>;
				reg-shift = <2>;
				dma-channel = <6>;
				no-loopback-test;
				status = "disabled";
			};

			dma_uart5: dma_uart5@1e790300{
				compatible = "aspeed,ast-sdma-uart";
				reg = <0x1e790300 0x20>;
				interrupts = <GIC_SPI 60 IRQ_TYPE_LEVEL_HIGH>;
				clock-frequency = <1846154>;
				reg-shift = <2>;
				dma-channel = <7>;
				no-loopback-test;
				status = "disabled";
			};

			dma_uart6: dma_uart6@1e790400{
				compatible = "aspeed,ast-sdma-uart";
				reg = <0x1e790400 0x20>;
				interrupts = <GIC_SPI 61 IRQ_TYPE_LEVEL_HIGH>;
				clock-frequency = <1846154>;
				reg-shift = <2>;
				dma-channel = <8>;
				no-loopback-test;
				status = "disabled";
			};

			dma_uart7: dma_uart7@1e790500{
				compatible = "aspeed,ast-sdma-uart";
				reg = <0x1e790500 0x20>;
				interrupts = <GIC_SPI 62 IRQ_TYPE_LEVEL_HIGH>;
				clock-frequency = <1846154>;
				reg-shift = <2>;
				dma-channel = <9>;
				no-loopback-test;
				status = "disabled";
			};

			dma_uart8: dma_uart8@1e790600{
				compatible = "aspeed,ast-sdma-uart";
				reg = <0x1e790600 0x20>;
				interrupts = <GIC_SPI 63 IRQ_TYPE_LEVEL_HIGH>;
				clock-frequency = <1846154>;
				reg-shift = <2>;
				dma-channel = <10>;
				no-loopback-test;
				status = "disabled";
			};

			dma_uart9: dma_uart9@1e790700{
				compatible = "aspeed,ast-sdma-uart";
				reg = <0x1e790700 0x20>;
				interrupts = <GIC_SPI 64 IRQ_TYPE_LEVEL_HIGH>;
				clock-frequency = <1846154>;
				reg-shift = <2>;
				dma-channel = <11>;
				no-loopback-test;
				status = "disabled";
			};

			i3c: bus@1e7a0000 {
				compatible = "simple-bus";
				#address-cells = <1>;
				#size-cells = <1>;
				ranges = <0 0x1e7a0000 0x8000>;
			};

		};

	};

};

&peci {
	peci0: peci-bus@0 {
		compatible = "aspeed,ast2600-peci";
		reg = <0x0 0x100>;
		#address-cells = <1>;
		#size-cells = <0>;
		interrupts = <GIC_SPI 38 IRQ_TYPE_LEVEL_HIGH>;
		clocks = <&syscon ASPEED_CLK_GATE_REF1CLK>, <&syscon ASPEED_CLK_AHB>;
		resets = <&syscon ASPEED_RESET_PECI>;
		clock-frequency = <25000000>; //target peci clk 
		clk-div = <1>;
		msg-timing = <3>;
		addr-timing = <3>;
		rd-sampling-point = <8>;
		cmd-timeout-ms = <1000>;
		64byte-mode;
		status = "disabled";
	};
};

&i2c {
	i2cglobal: i2cg@00 {
		compatible = "aspeed,ast2600-i2c-global", "syscon", "simple-mfd";
		resets = <&syscon ASPEED_RESET_I2C>;
		reg = <0x0 0x40>;
		clocks = <&syscon ASPEED_CLK_APB2>;
#if 1
		new-mode;
#endif
	};

	i2c0: i2c@80 {
		#address-cells = <1>;
		#size-cells = <0>;
		#interrupt-cells = <1>;

		reg = <0x80 0x80 0xC00 0x20>;
		compatible = "aspeed,ast2600-i2c-bus";
		clocks = <&syscon ASPEED_CLK_APB2>;
		bus-frequency = <100000>;
		interrupts = <GIC_SPI 110 IRQ_TYPE_LEVEL_HIGH>;
		pinctrl-names = "default";
		pinctrl-0 = <&pinctrl_i2c1_default>;

		status = "disabled";
	};

	i2c1: i2c@100 {
		#address-cells = <1>;
		#size-cells = <0>;
		#interrupt-cells = <1>;

		reg = <0x100 0x80 0xC20 0x20>;
		compatible = "aspeed,ast2600-i2c-bus";
		clocks = <&syscon ASPEED_CLK_APB2>;
		bus-frequency = <100000>;
		interrupts = <GIC_SPI 111 IRQ_TYPE_LEVEL_HIGH>;
		pinctrl-names = "default";
		pinctrl-0 = <&pinctrl_i2c2_default>;

		status = "disabled";
	};

	i2c2: i2c@180 {
		#address-cells = <1>;
		#size-cells = <0>;
		#interrupt-cells = <1>;

		reg = <0x180 0x80 0xC40 0x20>;
		compatible = "aspeed,ast2600-i2c-bus";
		clocks = <&syscon ASPEED_CLK_APB2>;
		bus-frequency = <100000>;
		interrupts = <GIC_SPI 112 IRQ_TYPE_LEVEL_HIGH>;
		pinctrl-names = "default";
		pinctrl-0 = <&pinctrl_i2c3_default>;

		status = "disabled";
	};

	i2c3: i2c@200 {
		#address-cells = <1>;
		#size-cells = <0>;
		#interrupt-cells = <1>;

		reg = <0x200 0x40 0xC60 0x20>;
		compatible = "aspeed,ast2600-i2c-bus";
		clocks = <&syscon ASPEED_CLK_APB2>;
		bus-frequency = <100000>;
		interrupts = <GIC_SPI 113 IRQ_TYPE_LEVEL_HIGH>;
		pinctrl-names = "default";
                pinctrl-0 = <&pinctrl_i2c4_default>;

		status = "disabled";
	};

	i2c4: i2c@280 {
		#address-cells = <1>;
		#size-cells = <0>;
		#interrupt-cells = <1>;

		reg = <0x280 0x80 0xC80 0x20>;
		compatible = "aspeed,ast2600-i2c-bus";
		clocks = <&syscon ASPEED_CLK_APB2>;
		bus-frequency = <100000>;
		interrupts = <GIC_SPI 114 IRQ_TYPE_LEVEL_HIGH>;
		pinctrl-names = "default";
		pinctrl-0 = <&pinctrl_i2c5_default>;

		status = "disabled";
	};

	i2c5: i2c@300 {
		#address-cells = <1>;
		#size-cells = <0>;
		#interrupt-cells = <1>;

		reg = <0x300 0x40 0xCA0 0x20>;
		compatible = "aspeed,ast2600-i2c-bus";
		clocks = <&syscon ASPEED_CLK_APB2>;
		bus-frequency = <100000>;
		interrupts = <GIC_SPI 115 IRQ_TYPE_LEVEL_HIGH>;
		pinctrl-names = "default";
		pinctrl-0 = <&pinctrl_i2c6_default>;

		status = "disabled";
	};

	i2c6: i2c@380 {
		#address-cells = <1>;
		#size-cells = <0>;
		#interrupt-cells = <1>;

		reg = <0x380 0x80 0xCC0 0x20>;
		compatible = "aspeed,ast2600-i2c-bus";
		clocks = <&syscon ASPEED_CLK_APB2>;
		bus-frequency = <100000>;
		interrupts = <GIC_SPI 116 IRQ_TYPE_LEVEL_HIGH>;
		pinctrl-names = "default";
		pinctrl-0 = <&pinctrl_i2c7_default>;

		status = "disabled";
	};

	i2c7: i2c@400 {
		#address-cells = <1>;
		#size-cells = <0>;
		#interrupt-cells = <1>;

		reg = <0x400 0x80 0xCE0 0x20>;
		compatible = "aspeed,ast2600-i2c-bus";
		clocks = <&syscon ASPEED_CLK_APB2>;
		bus-frequency = <100000>;
		interrupts = <GIC_SPI 117 IRQ_TYPE_LEVEL_HIGH>;
		pinctrl-names = "default";
                pinctrl-0 = <&pinctrl_i2c8_default>;

		status = "disabled";
	};

	i2c8: i2c@480 {
		#address-cells = <1>;
		#size-cells = <0>;
		#interrupt-cells = <1>;

		reg = <0x480 0x80 0xD00 0x20>;
		compatible = "aspeed,ast2600-i2c-bus";
		clocks = <&syscon ASPEED_CLK_APB2>;
		bus-frequency = <100000>;
		interrupts = <GIC_SPI 118 IRQ_TYPE_LEVEL_HIGH>;
		pinctrl-names = "default";
		pinctrl-0 = <&pinctrl_i2c9_default>;

		status = "disabled";
	};

	i2c9: i2c@500 {
		#address-cells = <1>;
		#size-cells = <0>;
		#interrupt-cells = <1>;

		reg = <0x500 0x80 0xD20 0x20>;
		compatible = "aspeed,ast2600-i2c-bus";
		clocks = <&syscon ASPEED_CLK_APB2>;
		bus-frequency = <100000>;
		interrupts = <GIC_SPI 119 IRQ_TYPE_LEVEL_HIGH>;
		pinctrl-names = "default";
		pinctrl-0 = <&pinctrl_i2c10_default>;

		status = "disabled";
	};

	i2c10: i2c@580 {
		#address-cells = <1>;
		#size-cells = <0>;
		#interrupt-cells = <1>;

		reg = <0x580 0x80 0xD40 0x20>;
		compatible = "aspeed,ast2600-i2c-bus";
		clocks = <&syscon ASPEED_CLK_APB2>;
		bus-frequency = <100000>;
		interrupts = <GIC_SPI 120 IRQ_TYPE_LEVEL_HIGH>;
		pinctrl-names = "default";
		pinctrl-0 = <&pinctrl_i2c11_default>;

		status = "disabled";
	};

	i2c11: i2c@600 {
		#address-cells = <1>;
		#size-cells = <0>;
		#interrupt-cells = <1>;

		reg = <0x600 0x80 0xD60 0x20>;
		compatible = "aspeed,ast2600-i2c-bus";
		clocks = <&syscon ASPEED_CLK_APB2>;
		bus-frequency = <100000>;
		interrupts = <GIC_SPI 121 IRQ_TYPE_LEVEL_HIGH>;
		pinctrl-names = "default";
		pinctrl-0 = <&pinctrl_i2c12_default>;

		status = "disabled";
	};

	i2c12: i2c@680 {
		#address-cells = <1>;
		#size-cells = <0>;
		#interrupt-cells = <1>;

		reg = <0x680 0x80 0xD80 0x20>;
		compatible = "aspeed,ast2600-i2c-bus";
		clocks = <&syscon ASPEED_CLK_APB2>;
		bus-frequency = <100000>;
		interrupts = <GIC_SPI 122 IRQ_TYPE_LEVEL_HIGH>;
		pinctrl-names = "default";
                pinctrl-0 = <&pinctrl_i2c13_default>;

		status = "disabled";
	};

	i2c13: i2c@700 {
		#address-cells = <1>;
		#size-cells = <0>;
		#interrupt-cells = <1>;

		reg = <0x700 0x80 0xDA0 0x20>;
		compatible = "aspeed,ast2600-i2c-bus";
		clocks = <&syscon ASPEED_CLK_APB2>;
		bus-frequency = <100000>;
		interrupts = <GIC_SPI 123 IRQ_TYPE_LEVEL_HIGH>;
		pinctrl-names = "default";
		pinctrl-0 = <&pinctrl_i2c14_default>;

		status = "disabled";
	};

	i2c14: i2c@780 {
		#address-cells = <1>;
		#size-cells = <0>;
		#interrupt-cells = <1>;

		reg = <0x780 0x80 0xDC0 0x20>;
		compatible = "aspeed,ast2600-i2c-bus";
		clocks = <&syscon ASPEED_CLK_APB2>;
		bus-frequency = <100000>;
		interrupts = <GIC_SPI 124 IRQ_TYPE_LEVEL_HIGH>;
		pinctrl-names = "default";
		pinctrl-0 = <&pinctrl_i2c15_default>;

		status = "disabled";
	};

	i2c15: i2c@800 {
		#address-cells = <1>;
		#size-cells = <0>;
		#interrupt-cells = <1>;

		reg = <0x800 0x80 0xDE0 0x20>;
		compatible = "aspeed,ast2600-i2c-bus";
		clocks = <&syscon ASPEED_CLK_APB2>;
		bus-frequency = <100000>;
		interrupts = <GIC_SPI 125 IRQ_TYPE_LEVEL_HIGH>;
		pinctrl-names = "default";
		pinctrl-0 = <&pinctrl_i2c16_default>;

		status = "disabled";
	};

};

&i3c{
	i3cglobal: i3cg@00 {
		reg = <0x0 0x1000>;
		compatible = "aspeed,ast2600-i3c-global";
		resets = <&syscon ASPEED_RESET_I3C>;
	};

	i3c0: i3c0@2000 {
		#address-cells = <1>;
		#size-cells = <0>;
		#interrupt-cells = <1>;

		reg = <0x2000 0x1000>;
		compatible = "snps,dw-i3c-master-1.00a";
		clocks = <&syscon ASPEED_CLK_GATE_I3C0CLK>;
		resets = <&syscon ASPEED_RESET_I3C0>;
		bus-frequency = <100000>;
		interrupts = <GIC_SPI 102 IRQ_TYPE_LEVEL_HIGH>;
		pinctrl-names = "default";
		pinctrl-0 = <&pinctrl_i3c1_default>;

		status = "disabled";
	};

	i3c1: i3c1@3000 {
		#address-cells = <1>;
		#size-cells = <0>;
		#interrupt-cells = <1>;

		reg = <0x3000 0x1000>;
		compatible = "snps,dw-i3c-master-1.00a";
		clocks = <&syscon ASPEED_CLK_GATE_I3C1CLK>;
		resets = <&syscon ASPEED_RESET_I3C1>;
		bus-frequency = <100000>;
		interrupts = <GIC_SPI 103 IRQ_TYPE_LEVEL_HIGH>;
		pinctrl-names = "default";
		pinctrl-0 = <&pinctrl_i3c2_default>;

		status = "disabled";
	};

	i3c2: i3c2@4000 {
		#address-cells = <1>;
		#size-cells = <0>;
		#interrupt-cells = <1>;

		reg = <0x4000 0x1000>;
		compatible = "snps,dw-i3c-master-1.00a";
		clocks = <&syscon ASPEED_CLK_GATE_I3C2CLK>;
		resets = <&syscon ASPEED_RESET_I3C2>;
		bus-frequency = <100000>;
		interrupts = <GIC_SPI 104 IRQ_TYPE_LEVEL_HIGH>;
		pinctrl-names = "default";
		pinctrl-0 = <&pinctrl_i3c3_default>;

		status = "disabled";
	};

	i3c3: i3c3@5000 {
		#address-cells = <1>;
		#size-cells = <0>;
		#interrupt-cells = <1>;

		reg = <0x5000 0x1000>;
		compatible = "snps,dw-i3c-master-1.00a";
		clocks = <&syscon ASPEED_CLK_GATE_I3C3CLK>;
		resets = <&syscon ASPEED_RESET_I3C3>;
		bus-frequency = <100000>;
		interrupts = <GIC_SPI 105 IRQ_TYPE_LEVEL_HIGH>;
		pinctrl-names = "default";
		pinctrl-0 = <&pinctrl_i3c4_default>;

		status = "disabled";
	};

	i3c4: i3c4@6000 {
		#address-cells = <1>;
		#size-cells = <0>;
		#interrupt-cells = <1>;

		reg = <0x6000 0x1000>;
		compatible = "snps,dw-i3c-master-1.00a";
		clocks = <&syscon ASPEED_CLK_GATE_I3C4CLK>;
		resets = <&syscon ASPEED_RESET_I3C4>;
		bus-frequency = <100000>;
		interrupts = <GIC_SPI 106 IRQ_TYPE_LEVEL_HIGH>;
		pinctrl-names = "default";
		pinctrl-0 = <&pinctrl_i3c5_default>;

		status = "disabled";
	};

	i3c5: i3c5@7000 {
		#address-cells = <1>;
		#size-cells = <0>;
		#interrupt-cells = <1>;

		reg = <0x7000 0x1000>;
		compatible = "snps,dw-i3c-master-1.00a";
		clocks = <&syscon ASPEED_CLK_GATE_I3C5CLK>;
		resets = <&syscon ASPEED_RESET_I3C5>;
		bus-frequency = <100000>;
		interrupts = <GIC_SPI 107 IRQ_TYPE_LEVEL_HIGH>;
		pinctrl-names = "default";
		pinctrl-0 = <&pinctrl_i3c6_default>;

		status = "disabled";
	};

};

&pinctrl {
	pinctrl_txd1_default: txd1_default {
		function = "TXD1";
		groups = "TXD1";
	};

	pinctrl_txd2_default: txd2_default {
		function = "TXD2";
		groups = "TXD2";
	};

	pinctrl_txd3_default: txd3_default {
		function = "TXD3";
		groups = "TXD3";
	};

	pinctrl_txd4_default: txd4_default {
		function = "TXD4";
		groups = "TXD4";
	};
	pinctrl_rxd1_default: rxd1_default {
		function = "RXD1";
		groups = "RXD1";
	};

	pinctrl_rxd2_default: rxd2_default {
		function = "RXD2";
		groups = "RXD2";
	};

	pinctrl_rxd3_default: rxd3_default {
		function = "RXD3";
		groups = "RXD3";
	};

	pinctrl_rxd4_default: rxd4_default {
		function = "RXD4";
		groups = "RXD4";
	};

	pinctrl_uart6_default: uart6_default {
        function = "UART6";
        groups = "UART6";
	};

	pinctrl_uart7_default: uart7_default {
		function = "UART7";
		groups = "UART7";
	};

	pinctrl_uart8_default: uart8_default {
		function = "UART8";
		groups = "UART8";
	};

	pinctrl_uart9_default: uart9_default {
		function = "UART9";
		groups = "UART9";
	};

	pinctrl_uart10_default: uart10_default {
		function = "UART10";
		groups = "UART10";
	};

	pinctrl_uart11_default: uart11_default {
		function = "UART11";
		groups = "UART11";
	};

	pinctrl_uart12g0_default: uart12g0_default {
        function = "UART12";
        groups = "UART12G0";
	};

	pinctrl_uart12g1_default: uart12g1_default {
		function = "UART12";
		groups = "UART12G1";
	};

	pinctrl_uart13g0_default: uart13g0_default {
		function = "UART13";
		groups = "UART13G0";
	};

	pinctrl_uart13g1_default: uart13g1_default {
		function = "UART13";
		groups = "UART13G1";
	};

	pinctrl_adc0_default: adc0_default {
		function = "ADC0";
		groups = "ADC0";
	};

	pinctrl_adc1_default: adc1_default {
		function = "ADC1";
		groups = "ADC1";
	};

	pinctrl_adc10_default: adc10_default {
		function = "ADC10";
		groups = "ADC10";
	};

	pinctrl_adc11_default: adc11_default {
		function = "ADC11";
		groups = "ADC11";
	};

	pinctrl_adc12_default: adc12_default {
		function = "ADC12";
		groups = "ADC12";
	};

	pinctrl_adc13_default: adc13_default {
		function = "ADC13";
		groups = "ADC13";
	};

	pinctrl_adc14_default: adc14_default {
		function = "ADC14";
		groups = "ADC14";
	};

	pinctrl_adc15_default: adc15_default {
		function = "ADC15";
		groups = "ADC15";
	};

	pinctrl_adc2_default: adc2_default {
		function = "ADC2";
		groups = "ADC2";
	};

	pinctrl_adc3_default: adc3_default {
		function = "ADC3";
		groups = "ADC3";
	};

	pinctrl_adc4_default: adc4_default {
		function = "ADC4";
		groups = "ADC4";
	};

	pinctrl_adc5_default: adc5_default {
		function = "ADC5";
		groups = "ADC5";
	};

	pinctrl_adc6_default: adc6_default {
		function = "ADC6";
		groups = "ADC6";
	};

	pinctrl_adc7_default: adc7_default {
		function = "ADC7";
		groups = "ADC7";
	};

	pinctrl_adc8_default: adc8_default {
		function = "ADC8";
		groups = "ADC8";
	};

	pinctrl_adc9_default: adc9_default {
		function = "ADC9";
		groups = "ADC9";
	};

	pinctrl_rgmii1_default: rgmii1_default {
		function = "RGMII1";
		groups = "RGMII1";
	};
	pinctrl_rgmii2_default: rgmii2_default {
		function = "RGMII2";
		groups = "RGMII2";
	};

	pinctrl_rgmii3_default: rgmii3_default {
		function = "RGMII3";
		groups = "RGMII3";
	};

	pinctrl_rgmii4_default: rgmii4_default {
		function = "RGMII4";
		groups = "RGMII4";
	};

	pinctrl_rmii1_default: rmii1_default {
		function = "RMII1";
		groups = "RMII1";
	};

	pinctrl_rmii2_default: rmii2_default {
		function = "RMII2";
		groups = "RMII2";
	};

	pinctrl_rmii3_default: rmii3_default {
		function = "RMII3";
		groups = "RMII3";
	};

	pinctrl_rmii4_default: rmii4_default {
		function = "RMII4";
		groups = "RMII4";
	};

	pinctrl_mac1link_default: mac1link_default {
		function = "MAC1LINK";
		groups = "MAC1LINK";
	};

	pinctrl_mac2link_default: mac2link_default {
		function = "MAC2LINK";
		groups = "MAC2LINK";
	};

	pinctrl_mac3link_default: mac3link_default {
		function = "MAC3LINK";
		groups = "MAC3LINK";
	};

	pinctrl_mac4link_default: mac4link_default {
		function = "MAC4LINK";
		groups = "MAC4LINK";
	};

	pinctrl_mdio1_default: mdio1_default {
		function = "MDIO1";
		groups = "MDIO1";
	};

	pinctrl_mdio2_default: mdio2_default {
		function = "MDIO2";
		groups = "MDIO2";
	};

	pinctrl_mdio3_default: mdio3_default {
		function = "MDIO3";
		groups = "MDIO3";
	};
	pinctrl_mdio4_default: mdio4_default {
		function = "MDIO4";
		groups = "MDIO4";
	};

	pinctrl_usb2ah_default: usb2ah_default {
		function = "USB2AH";
		groups = "USB2AH";
	};
	pinctrl_usb2ad_default: usb2ad_default {
		function = "USB2AD";
		groups = "USB2AD";
	};

	pinctrl_usb2adp_default: usb2adp_default {
		function = "USB2ADP";
		groups = "USB2ADP";
	};

	pinctrl_usb11bhid_default: usb11bhid_default {
		function = "USB11BHID";
		groups = "USB11BHID";
	};

	pinctrl_usb2bd_default: usb2bd_default {
		function = "USB2BD";
		groups = "USB2BD";
	};

	pinctrl_usb2bh_default: usb2bh_default {
		function = "USB2BH";
		groups = "USB2BH";
	};

	pinctrl_tach0_default: tach0_default {
		function = "TACH0";
		groups = "TACH0";
	};

	pinctrl_tach1_default: tach1_default {
		function = "TACH1";
		groups = "TACH1";
	};

	pinctrl_tach2_default: tach2_default {
		function = "TACH2";
		groups = "TACH2";
	};

	pinctrl_tach3_default: tach3_default {
		function = "TACH3";
		groups = "TACH3";
	};
	pinctrl_tach4_default: tach4_default {
		function = "TACH4";
		groups = "TACH4";
	};
	pinctrl_tach5_default: tach5_default {
		function = "TACH5";
		groups = "TACH5";
	};
	pinctrl_tach6_default: tach6_default {
		function = "TACH6";
		groups = "TACH6";
	};
	pinctrl_tach7_default: tach7_default {
		function = "TACH7";
		groups = "TACH7";
	};
	pinctrl_tach8_default: tach8_default {
		function = "TACH8";
		groups = "TACH8";
	};
	pinctrl_tach9_default: tach9_default {
		function = "TACH9";
		groups = "TACH9";
	};
	pinctrl_tach10_default: tach10_default {
		function = "TACH10";
		groups = "TACH10";
	};
	pinctrl_tach11_default: tach11_default {
		function = "TACH11";
		groups = "TACH11";
	};
	pinctrl_tach12_default: tach12_default {
		function = "TACH12";
		groups = "TACH12";
	};
	pinctrl_tach13_default: tach13_default {
		function = "TACH13";
		groups = "TACH13";
	};
	pinctrl_tach14_default: tach14_default {
		function = "TACH14";
		groups = "TACH14";
	};
	pinctrl_tach15_default: tach15_default {
		function = "TACH15";
		groups = "TACH15";
	};

	pinctrl_pwm0_default: pwm0_default {
		function = "PWM0";
		groups = "PWM0";
	};

	pinctrl_pwm1_default: pwm1_default {
		function = "PWM1";
		groups = "PWM1";
	};

	pinctrl_pwm2_default: pwm2_default {
		function = "PWM2";
		groups = "PWM2";
	};

	pinctrl_pwm3_default: pwm3_default {
		function = "PWM3";
		groups = "PWM3";
	};

	pinctrl_pwm4_default: pwm4_default {
		function = "PWM4";
		groups = "PWM4";
	};

	pinctrl_pwm5_default: pwm5_default {
		function = "PWM5";
		groups = "PWM5";
	};

	pinctrl_pwm6_default: pwm6_default {
		function = "PWM6";
		groups = "PWM6";
	};

	pinctrl_pwm7_default: pwm7_default {
		function = "PWM7";
		groups = "PWM7";
	};

	pinctrl_pwm8g0_default: pwm8g0_default {
		function = "PWM8";
		groups = "PWM8G0";
	};

	pinctrl_pwm8g1_default: pwm8g1_default {
		function = "PWM8";
		groups = "PWM8G1";
	};

	pinctrl_pwm9g0_default: pwm9g0_default {
		function = "PWM9";
		groups = "PWM9G0";
	};

	pinctrl_pwm9g1_default: pwm9g1_default {
		function = "PWM9";
		groups = "PWM9G1";
	};

	pinctrl_pwm10g0_default: pwm10g0_default {
		function = "PWM10";
		groups = "PWM10G0";
	};

	pinctrl_pwm10g1_default: pwm10g1_default {
		function = "PWM10";
		groups = "PWM10G1";
	};

	pinctrl_pwm11g0_default: pwm11g0_default {
		function = "PWM11";
		groups = "PWM11G0";
	};

	pinctrl_pwm11g1_default: pwm11g1_default {
		function = "PWM11";
		groups = "PWM11G1";
	};

	pinctrl_pwm12g0_default: pwm12g0_default {
		function = "PWM12";
		groups = "PWM12G0";
	};

	pinctrl_pwm12g1_default: pwm12g1_default {
		function = "PWM12";
		groups = "PWM12G1";
	};

	pinctrl_pwm13g0_default: pwm13g0_default {
		function = "PWM13";
		groups = "PWM13G0";
	};

	pinctrl_pwm13g1_default: pwm13g1_default {
		function = "PWM13";
		groups = "PWM13G1";
	};

	pinctrl_pwm14g0_default: pwm14g0_default {
		function = "PWM14";
		groups = "PWM14G0";
	};

	pinctrl_pwm14g1_default: pwm14g1_default {
		function = "PWM14";
		groups = "PWM14G1";
	};

	pinctrl_pwm15g0_default: pwm15g0_default {
		function = "PWM15";
		groups = "PWM15G0";
	};

	pinctrl_pwm15g1_default: pwm15g1_default {
		function = "PWM15";
		groups = "PWM15G1";
	};

	pinctrl_sd1_default: sd1_default {
		function = "SD1";
		groups = "SD1";
	};
#if 0
	pinctrl_sd1_8bits_default: sd1_8bits_default {
		function = "SD1_8BITS";
		groups = "SD1_8BITS";
	};
#endif
	pinctrl_sd2_default: sd2_default {
		function = "SD2";
		groups = "SD2";
	};

	pinctrl_emmc_default: emmc_default {
		function = "EMMC";
		groups = "EMMC";
	};

	pinctrl_i2c1_default: i2c1_default {
		function = "I2C1";
		groups = "I2C1";
	};

	pinctrl_salt1_default: salt1_default {
		function = "SALT1";
		groups = "SALT1";
	};

	pinctrl_i2c2_default: i2c2_default {
		function = "I2C2";
		groups = "I2C2";
	};

	pinctrl_salt2_default: salt2_default {
		function = "SALT2";
		groups = "SALT2";
	};

	pinctrl_i2c3_default: i2c3_default {
		function = "I2C3";
		groups = "I2C3";
	};

	pinctrl_salt3_default: salt3_default {
		function = "SALT3";
		groups = "SALT3";
	};

	pinctrl_i2c4_default: i2c4_default {
		function = "I2C4";
		groups = "I2C4";
	};

	pinctrl_salt4_default: salt4_default {
		function = "SALT4";
		groups = "SALT4";
	};

	pinctrl_i2c5_default: i2c5_default {
		function = "I2C5";
		groups = "I2C5";
	};

	pinctrl_salt5_default: salt5_default {
		function = "SALT5";
		groups = "SALT5";
	};

	pinctrl_i2c6_default: i2c6_default {
		function = "I2C6";
		groups = "I2C6";
	};

	pinctrl_salt6_default: salt6_default {
		function = "SALT6";
		groups = "SALT6";
	};

	pinctrl_i2c7_default: i2c7_default {
		function = "I2C7";
		groups = "I2C7";
	};

	pinctrl_salt7_default: salt7_default {
		function = "SALT7";
		groups = "SALT7";
	};

	pinctrl_i2c8_default: i2c8_default {
		function = "I2C8";
		groups = "I2C8";
	};

	pinctrl_salt8_default: salt8_default {
		function = "SALT8";
		groups = "SALT8";
	};

	pinctrl_i2c9_default: i2c9_default {
		function = "I2C9";
		groups = "I2C9";
	};

	pinctrl_salt9g0_default: salt9g0_default {
		function = "SALT9";
		groups = "SALT9G0";
	};

	pinctrl_salt9g1_default: salt9g1_default {
		function = "SALT9";
		groups = "SALT9G1";
	};

	pinctrl_i2c10_default: i2c10_default {
		function = "I2C10";
		groups = "I2C10";
	};

	pinctrl_salt10g0_default: salt10g0_default {
		function = "SALT10";
		groups = "SALT10G0";
	};

	pinctrl_salt10g1_default: salt10g1_default {
		function = "SALT10";
		groups = "SALT10G1";
	};

	pinctrl_i2c11_default: i2c11_default {
		function = "I2C11";
		groups = "I2C11";
	};

	pinctrl_salt11g0_default: salt11g0_default {
		function = "SALT11";
		groups = "SALT11G0";
	};

	pinctrl_salt11g1_default: salt11g1_default {
		function = "SALT11";
		groups = "SALT11G1";
	};

	pinctrl_i2c12_default: i2c12_default {
		function = "I2C12";
		groups = "I2C12";
	};

	pinctrl_salt12g0_default: salt12g0_default {
		function = "SALT12";
		groups = "SALT12G0";
	};

	pinctrl_salt12g1_default: salt12g1_default {
		function = "SALT12";
		groups = "SALT12G1";
	};

	pinctrl_i2c13_default: i2c13_default {
		function = "I2C13";
		groups = "I2C13";
	};

	pinctrl_salt13g0_default: salt13g0_default {
		function = "SALT13";
		groups = "SALT13G0";
	};

	pinctrl_salt13g1_default: salt13g1_default {
		function = "SALT13";
		groups = "SALT13G1";
	};

	pinctrl_i2c14_default: i2c14_default {
		function = "I2C14";
		groups = "I2C14";
	};

	pinctrl_salt14g0_default: salt14g0_default {
		function = "SALT14";
		groups = "SALT14G0";
	};

	pinctrl_salt14g1_default: salt14g1_default {
		function = "SALT14";
		groups = "SALT14G1";
	};

	pinctrl_i2c15_default: i2c15_default {
		function = "I2C15";
		groups = "I2C15";
	};

	pinctrl_salt15g0_default: salt15g0_default {
		function = "SALT15";
		groups = "SALT15G0";
	};

	pinctrl_salt15g1_default: salt15g1_default {
		function = "SALT15";
		groups = "SALT15G1";
	};

	pinctrl_i2c16_default: i2c16_default {
		function = "I2C16";
		groups = "I2C16";
	};

	pinctrl_salt16g0_default: salt16g0_default {
		function = "SALT16";
		groups = "SALT16G0";
	};

	pinctrl_salt16g1_default: salt16g1_default {
		function = "SALT16";
		groups = "SALT16G1";
	};

	pinctrl_i3c1_default: i3c1_default {
                function = "I3C1";
                groups = "I3C1";
        };

	pinctrl_i3c2_default: i3c2_default {
                function = "I3C2";
                groups = "I3C2";
        };

	pinctrl_i3c3_default: i3c3_default {
                function = "I3C3";
                groups = "I3C3";
        };

	pinctrl_i3c4_default: i3c4_default {
                function = "I3C4";
                groups = "I3C4";
        };

	pinctrl_i3c5_default: i3c5_default {
                function = "I3C5";
                groups = "I3C5";
        };

	pinctrl_i3c6_default: i3c6_default {
                function = "I3C6";
                groups = "I3C6";
        };

	pinctrl_jtagm_default: jtagm_default {
		function = "JTAGM";
		groups = "JTAGM";
	};
};
